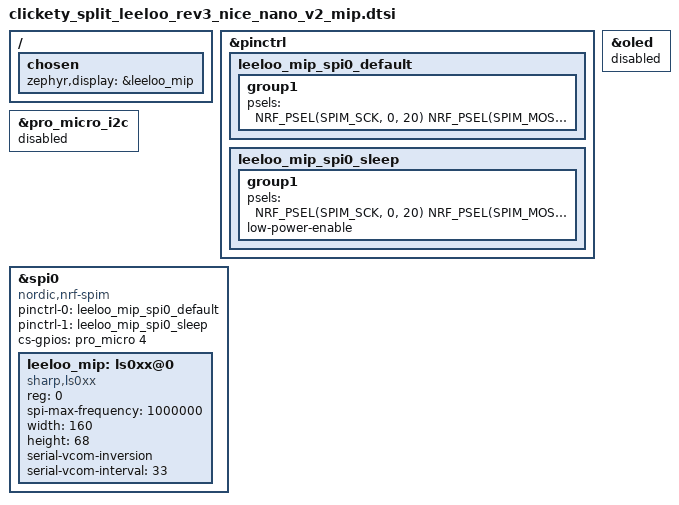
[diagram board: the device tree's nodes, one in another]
/*
 * Copyright (c) 2026 Clickety Split Ltd.
 * SPDX-License-Identifier: MIT
 *
 * Leeloo rev3 nice!nano v2 Sharp memory-in-pixel display wiring.
 *
 * This definition is owned by the Leeloo shield and intentionally does not
 * depend on the nice_view or nice_view_adapter shields.
 */

/ {
    chosen {
        zephyr,display = &leeloo_mip;
    };
};

&pinctrl {
    leeloo_mip_spi0_default: leeloo_mip_spi0_default {
        group1 {
            psels = <
                NRF_PSEL(SPIM_SCK, 0, 20)
                NRF_PSEL(SPIM_MOSI, 0, 17)
            >;
        };
    };

    leeloo_mip_spi0_sleep: leeloo_mip_spi0_sleep {
        group1 {
            psels = <
                NRF_PSEL(SPIM_SCK, 0, 20)
                NRF_PSEL(SPIM_MOSI, 0, 17)
            >;
            low-power-enable;
        };
    };
};

/*
 * SPI0 and I2C0 are alternate personalities of the same nRF52840 peripheral.
 *
 * The nice!nano board definition includes an SSD1306 OLED on pro_micro_i2c.
 * Disable both the child and its bus before configuring peripheral zero as
 * the Leeloo MIP display SPI bus.
 */
&oled {
    status = "disabled";
};

&pro_micro_i2c {
    status = "disabled";
};

&spi0 {
    compatible = "nordic,nrf-spim";
    status = "okay";

    pinctrl-0 = <&leeloo_mip_spi0_default>;
    pinctrl-1 = <&leeloo_mip_spi0_sleep>;
    pinctrl-names = "default", "sleep";

    /* Leeloo routes the display chip-select signal to Pro Micro pin 4. */
    cs-gpios = <&pro_micro 4 GPIO_ACTIVE_HIGH>;

    leeloo_mip: ls0xx@0 {
        compatible = "sharp,ls0xx";
        status = "okay";

        reg = <0>;
        spi-max-frequency = <1000000>;

        width = <160>;
        height = <68>;

        /*
         * nice!view performs VCOM inversion through the serial protocol.
         * The interval matches the standard ZMK nice!view definition.
         */
        serial-vcom-inversion;
        serial-vcom-interval = <33>;
    };
};
